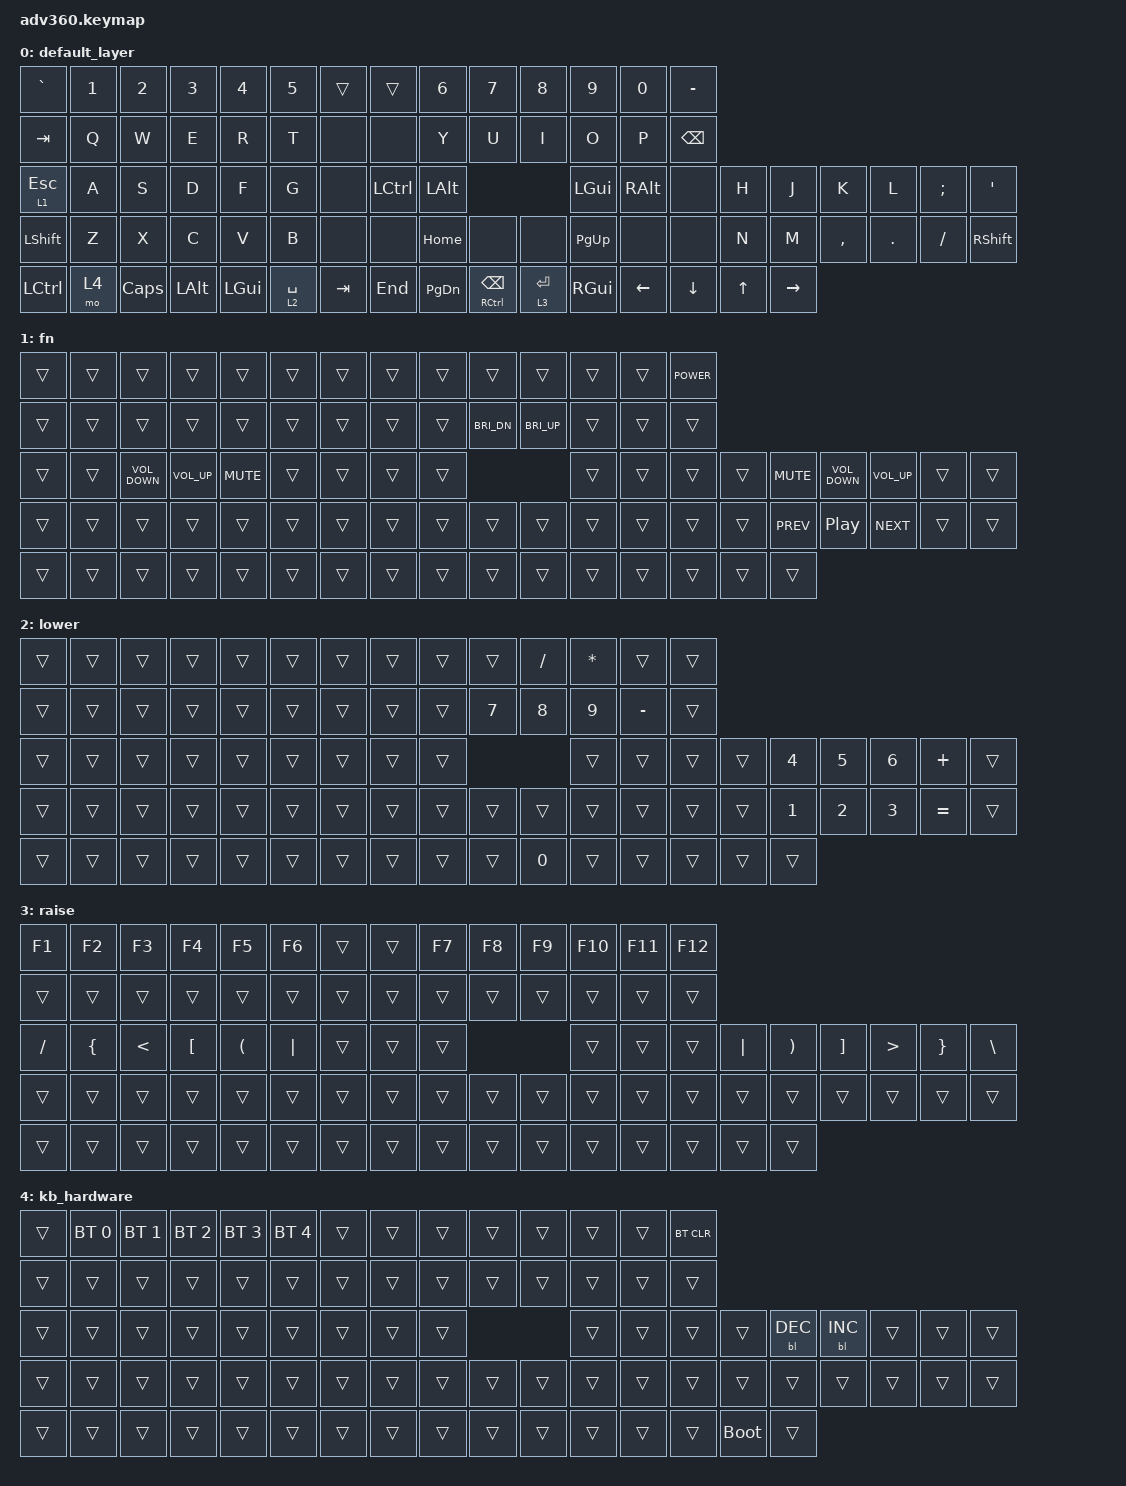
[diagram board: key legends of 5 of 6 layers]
#include <behaviors.dtsi>
#include <dt-bindings/zmk/keys.h>
#include <dt-bindings/zmk/bt.h>
#include <dt-bindings/zmk/rgb.h>
#include <dt-bindings/zmk/backlight.h>
#include <dt-bindings/zmk/pointing.h>

/ {
    behaviors {
        #include "macros.dtsi"

        hm: homerow_mods {
            compatible = "zmk,behavior-hold-tap";
            label = "HOMEROW_MODS";
            #binding-cells = <2>;
            tapping-term-ms = <200>;
            quick_tap_ms = <175>;
            flavor = "tap-preferred";
            bindings =
                <&kp>,
                <&kp>;
        };
    };

    keymap {
        compatible = "zmk,keymap";

        default_layer {
            bindings = <
 &kp GRAVE  &kp N1    &kp N2    &kp N3    &kp N4       &kp N5   &trans     &trans     &kp N6               &kp N7       &kp N8         &kp N9         &kp N0      &kp MINUS
   &kp TAB   &kp Q     &kp W     &kp E     &kp R        &kp T    &none      &none      &kp Y                &kp U        &kp I          &kp O          &kp P  &kp BACKSPACE
 &lt 1 ESC   &kp A     &kp S     &kp D     &kp F        &kp G    &none  &kp LCTRL   &kp LALT                                         &kp LGUI  &kp RIGHT_ALT          &none   &kp H      &kp J      &kp K    &kp L  &kp SEMI    &kp SQT
 &kp LSHFT   &kp Z     &kp X     &kp C     &kp V        &kp B    &none      &none   &kp HOME                &none        &none      &kp PG_UP          &none          &none   &kp N      &kp M  &kp COMMA  &kp DOT  &kp FSLH  &kp RSHFT
 &kp LCTRL   &mo 4  &kp CAPS  &kp LALT  &kp LGUI  &lt 2 SPACE  &kp TAB    &kp END  &kp PG_DN  &mt RCTRL BACKSPACE  &lt 3 ENTER  &kp RIGHT_GUI       &kp LEFT       &kp DOWN  &kp UP  &kp RIGHT
            >;
        };

        fn {
            bindings = <
 &trans  &trans             &trans           &trans      &trans  &trans  &trans  &trans  &trans        &trans        &trans  &trans  &trans  &kp C_POWER
 &trans  &trans             &trans           &trans      &trans  &trans  &trans  &trans  &trans  &kp C_BRI_DN  &kp C_BRI_UP  &trans  &trans       &trans
 &trans  &trans  &kp C_VOLUME_DOWN  &kp C_VOLUME_UP  &kp K_MUTE  &trans  &trans  &trans  &trans                              &trans  &trans       &trans  &trans  &kp K_MUTE  &kp C_VOLUME_DOWN  &kp C_VOLUME_UP  &trans  &trans
 &trans  &trans             &trans           &trans      &trans  &trans  &trans  &trans  &trans        &trans        &trans  &trans  &trans       &trans  &trans  &kp C_PREV   &kp C_PLAY_PAUSE       &kp C_NEXT  &trans  &trans
 &trans  &trans             &trans           &trans      &trans  &trans  &trans  &trans  &trans        &trans        &trans  &trans  &trans       &trans  &trans      &trans
            >;
        };

        lower {
            bindings = <
 &trans  &trans  &trans  &trans  &trans  &trans  &trans  &trans  &trans        &trans     &kp SLASH     &kp ASTRK     &trans  &trans
 &trans  &trans  &trans  &trans  &trans  &trans  &trans  &trans  &trans  &kp NUMBER_7  &kp NUMBER_8  &kp NUMBER_9  &kp MINUS  &trans
 &trans  &trans  &trans  &trans  &trans  &trans  &trans  &trans  &trans                                    &trans     &trans  &trans  &trans  &kp NUMBER_4  &kp NUMBER_5  &kp NUMBER_6   &kp PLUS  &trans
 &trans  &trans  &trans  &trans  &trans  &trans  &trans  &trans  &trans        &trans        &trans        &trans     &trans  &trans  &trans  &kp NUMBER_1  &kp NUMBER_2  &kp NUMBER_3  &kp EQUAL  &trans
 &trans  &trans  &trans  &trans  &trans  &trans  &trans  &trans  &trans        &trans  &kp NUMBER_0        &trans     &trans  &trans  &trans        &trans
            >;
        };

        raise {
            bindings = <
    &kp F1          &kp F2         &kp F3            &kp F4                &kp F5    &kp F6  &trans  &trans  &kp F7  &kp F8  &kp F9  &kp F10  &kp F11  &kp F12
    &trans          &trans         &trans            &trans                &trans    &trans  &trans  &trans  &trans  &trans  &trans   &trans   &trans   &trans
 &kp SLASH  &kp LEFT_BRACE  &kp LESS_THAN  &kp LEFT_BRACKET  &kp LEFT_PARENTHESIS  &kp PIPE  &trans  &trans  &trans                   &trans   &trans   &trans  &kp PIPE  &kp RIGHT_PARENTHESIS  &kp RIGHT_BRACKET  &kp GREATER_THAN  &kp RIGHT_BRACE  &kp BACKSLASH
    &trans          &trans         &trans            &trans                &trans    &trans  &trans  &trans  &trans  &trans  &trans   &trans   &trans   &trans    &trans                 &trans             &trans            &trans           &trans         &trans
    &trans          &trans         &trans            &trans                &trans    &trans  &trans  &trans  &trans  &trans  &trans   &trans   &trans   &trans    &trans                 &trans
            >;
        };

        kb_hardware {
            bindings = <
 &trans  &bt BT_SEL 0  &bt BT_SEL 1  &bt BT_SEL 2  &bt BT_SEL 3  &bt BT_SEL 4  &trans  &trans  &trans  &trans  &trans  &trans  &trans  &bt BT_CLR
 &trans        &trans        &trans        &trans        &trans        &trans  &trans  &trans  &trans  &trans  &trans  &trans  &trans      &trans
 &trans        &trans        &trans        &trans        &trans        &trans  &trans  &trans  &trans                  &trans  &trans      &trans       &trans  &bl BL_DEC  &bl BL_INC  &trans  &trans  &trans
 &trans        &trans        &trans        &trans        &trans        &trans  &trans  &trans  &trans  &trans  &trans  &trans  &trans      &trans       &trans      &trans      &trans  &trans  &trans  &trans
 &trans        &trans        &trans        &trans        &trans        &trans  &trans  &trans  &trans  &trans  &trans  &trans  &trans      &trans  &bootloader      &trans
            >;
        };
||||||| 8c14317
    default_layer {
      bindings = <
        &kp EQUAL &kp N1    &kp N2   &kp N3   &kp N4     &kp N5 &tog 1                                                                       &mo 3 &kp N6 &kp N7 &kp N8    &kp N9   &kp N0   &kp MINUS
        &kp TAB   &kp Q     &kp W    &kp E    &kp R      &kp T  &none                                                                        &none &kp Y  &kp U  &kp I     &kp O    &kp P    &kp BSLH
        &kp ESC   &kp A     &kp S    &kp D    &kp F      &kp G  &none           &kp LCTRL &kp LALT &none &none &kp LGUI  &kp RCTRL           &none &kp H  &kp J  &kp K     &kp L    &kp SEMI &kp SQT
        &kp LSHFT &kp Z     &kp X    &kp C    &kp V      &kp B         &none    &none     &kp HOME &none &none &kp PG_UP &none     &none           &kp N  &kp M  &kp COMMA &kp DOT  &kp FSLH &kp RSHFT
        &mo 2     &kp GRAVE &kp CAPS &kp LEFT &kp RIGHT                &kp BSPC &kp DEL   &kp END              &kp PG_DN &kp ENTER &kp SPACE              &kp UP &kp DOWN  &kp LBKT &kp RBKT &mo 2
      >;
=======
    default_layer {
      display-name = "Base";
      bindings = <
        &kp EQUAL &kp N1    &kp N2   &kp N3   &kp N4     &kp N5 &tog 1                                                           &mo 3 &kp N6 &kp N7 &kp N8    &kp N9   &kp N0   &kp MINUS
        &kp TAB   &kp Q     &kp W    &kp E    &kp R      &kp T  &none                                                            &none &kp Y  &kp U  &kp I     &kp O    &kp P    &kp BSLH
        &kp ESC   &kp A     &kp S    &kp D    &kp F      &kp G  &none           &kp LCTRL &kp LALT &kp LGUI  &kp RCTRL           &none &kp H  &kp J  &kp K     &kp L    &kp SEMI &kp SQT
        &kp LSHFT &kp Z     &kp X    &kp C    &kp V      &kp B                            &kp HOME &kp PG_UP                           &kp N  &kp M  &kp COMMA &kp DOT  &kp FSLH &kp RSHFT
        &mo 2     &kp GRAVE &kp CAPS &kp LEFT &kp RIGHT                &kp BSPC &kp DEL   &kp END  &kp PG_DN &kp ENTER &kp SPACE              &kp UP &kp DOWN  &kp LBKT &kp RBKT &mo 2
      >;
>>>>>>> upstream/V3.0
    };
<<<<<<< HEAD
||||||| 8c14317
    keypad {
      bindings = <
        &kp EQUAL &kp N1    &kp N2   &kp N3   &kp N4     &kp N5 &trans                                                                       &mo 3 &kp N6 &kp KP_NUM &kp KP_EQUAL &kp KP_DIVIDE &kp KP_MULTIPLY &kp MINUS
        &kp TAB   &kp Q     &kp W    &kp E    &kp R      &kp T  &none                                                                        &none &kp Y  &kp KP_N7  &kp KP_N8    &kp KP_N9     &kp KP_MINUS    &kp BSLH
        &kp ESC   &kp A     &kp S    &kp D    &kp F      &kp G  &none           &kp LCTRL &kp LALT &none &none &kp LGUI  &kp RCTRL           &none &kp H  &kp KP_N4  &kp KP_N5    &kp KP_N6     &kp KP_PLUS     &kp SQT
        &kp LSHFT &kp Z     &kp X    &kp C    &kp V      &kp B         &none    &none     &kp HOME &none &none &kp PG_UP &none     &none           &kp N  &kp KP_N1  &kp KP_N2    &kp KP_N3     &kp KP_ENTER    &kp RSHFT
        &mo 2     &kp GRAVE &kp CAPS &kp LEFT &kp RIGHT                &kp BSPC &kp DEL   &kp END              &kp PG_DN &kp ENTER &kp KP_N0              &kp UP     &kp DOWN     &kp KP_DOT    &kp RBKT        &mo 2
      >;
    };
    fn {
      bindings = <
        &kp F1 &kp F2 &kp F3 &kp F4 &kp F5 &kp F6 &tog 1                                                       &mo 3 &kp F7 &kp F8 &kp F9 &kp F10 &kp F11 &kp F12
        &trans &trans &trans &trans &trans &trans  &none                                                       &none &trans &trans &trans &trans  &trans  &trans
        &trans &trans &trans &trans &trans &trans  &none        &trans &trans &none &none &trans &trans        &none &trans &trans &trans &trans  &trans  &trans
        &trans &trans &trans &trans &trans &trans        &none  &none  &trans &none &none &trans &none  &none        &trans &trans &trans &trans  &trans  &trans
        &trans &trans &trans &trans &trans               &trans &trans &trans             &trans &trans &trans              &trans &trans &trans  &trans  &trans
      >;
    };
    mod {
      bindings = <
        &none &bt BT_SEL 0 &bt BT_SEL 1 &bt BT_SEL 2 &bt BT_SEL 3 &bt BT_SEL 4 &none                                                                                                          &trans                 &bt BT_SEL 0 &bt BT_SEL 1 &bt BT_SEL 2 &bt BT_SEL 3 &bt BT_SEL 4 &none
        &none &none        &none        &none        &none        &none        &bootloader                                                                                                    &bootloader            &none        &none        &none        &none        &none        &none
        &none &none        &none        &none        &none        &none        &rgb_ug RGB_MEFS_CMD 5                 &bt BT_CLR &bt BT_CLR &none &none &bt BT_CLR &bt BT_CLR                 &rgb_ug RGB_MEFS_CMD 5 &none        &none        &none        &none        &none        &none
        &none &none        &none        &none        &none        &none                               &none           &none      &none      &none &none &none      &none      &none                                  &none        &none        &none        &none        &none        &none
        &none &none        &none        &bl BL_INC   &bl BL_DEC                                       &rgb_ug RGB_TOG &bl BL_TOG &none                  &none      &bl BL_TOG &rgb_ug RGB_TOG                                     &bl BL_INC   &bl BL_DEC   &none        &none        &none
      >;
    };
    };
};
